# PAC55XX register map
Vendor: Active-Semi; Series: PAC55XX; File version: 1.0
CPU: CM4 r0p1, little endian, MPU, FPU, vendor SysTick, 3 interrupt priority bits
Registers are 32-bit, read-write, reset 0x0 unless marked. A register's access mark holds for its fields unless they carry their own. Offsets are from the block's base; [hi:lo] are bit positions; {n}, {i} and the like mark numbered series.

## TimerD
Base 0x40090000
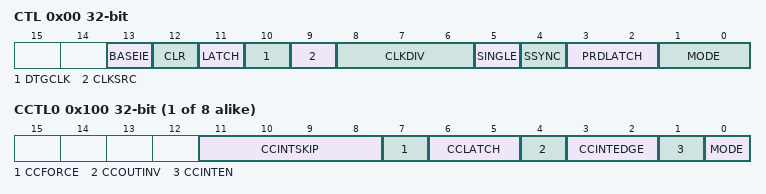
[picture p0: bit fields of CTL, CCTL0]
0x00 CTL — Timer D Control
  [13] BASEIE — Base timer interrupt enable
    0=Disabled (Base interrupt disabled); 1=Enabled (Base interrupt enabled)
  [12] CLR — Timer Clear
    0=Do not clear timer counter; 1=Clear timer counter
  [11] LATCH — Write 1 to Latch Period and all CCTRs
  [10] DTGCLK — Dead-Time Generator Clock Source
    0=Before Divider (Before input clock divider); 1=After Divider (After input clock divider)
  [9] CLKSRC — Timer Clock Source
    0=PCLK (PCLK selected as input to timer); 1=ACLK (ACLK selected as input to timer)
  [8:6] CLKDIV — Timer Input Clock Divider
    0=/1 (Timer input clock /1); 1=/2 (Timer input clock /2); 2=/4 (Timer input clock /4); 3=/8 (Timer input clock /8); 4=/16 (Timer input clock /16); 5=/32 (Timer input clock /32); 6=/64 (Timer input clock /64); 7=/128 (Timer input clock /128)
  [5] SINGLE — Single Shot Timer
    0=Disabled (Single Shot Disabled (auto-reload)); 1=Enabled (Single Shot Timer Enabled)
  [4] SSYNC — Timer Slave Synchronization
    0=Disabled (Slave Sync Disabled); 1=Enabled (Slave Sync Enabled)
  [3:2] PRDLATCH — Timer Period Latch Mode
    0=CTR=0 (Period is latched when CTR = 0); 1=CTR=Period (Period is latched when CTR = Period); 2=Immediate (Period is latched immediately upon register write)
  [1:0] MODE — Timer Mode
    0=Disabled Mode; 1=Up (Up Mode); 2=Up/Down Mode; 3=Asymmetric Mode
0x04 INT — Timer D Interrupt Control
0x08 PRD — Timer D Period
0x0C CTR — Timer D Counter
0x10 QEPCTL — Timer D QEP Control
{0x100+8i} CCTL{i} (i=0..7) — Timer D CC Control {i}
  [11:8] CCINTSKIP — CC Interrupt Skip Counter
    0=Don't skip CCR matches before interrupt; 1=Skip 1 CCR match before interrupt; {v}=Skip {v} CCR matches before interrupt (v=2..15)
  [7] CCFORCE — Write 1 to force compare event (self-clearing)
  [6:5] CCLATCH — CCR Register Latch Mode
    0=CTR=0/Rising (Compare(latch on CTR=0)/ Capture(latch on rising edge)); 1=CTR=Period/Falling (Compare(latch on CTR=Period)/ Capture(latch on falling edge)); 2=Immediate/Both (Compare(latch immediately)/ Capture(latch on both edges))
  [4] CCOUTINV — Invert CCR Output
    0=Not Inverted (Do not invert CCR output); 1=Inverted (Invert CCR output)
  [3:2] CCINTEDGE — Capture Mode Interrupt Edge Setting
    0=Rising Edge Interrupt; 1=Falling Edge Interrupt; 2=Both (Rising and Falling Edge Interrupt)
  [1] CCINTEN — CCR Interrupt Enable
    0=Disabled (CCR interrupt disabled); 1=Enabled (CCR interrupt enabled)
  [0] MODE — CCR Mode
    0=Compare Mode; 1=Capture Mode
{0x104+8i} CCTR{i} (i=0..7) — Timer D CC Counter {i}
{0x200+4i} DTGCTL{i} (i=0..3) — Timer D DTG Control {i}

## CAN — CAN Peripheral
Base 0x400A0000
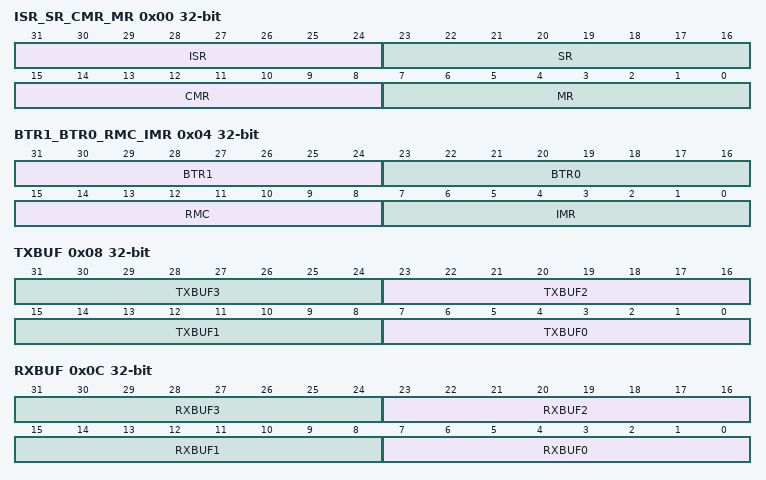
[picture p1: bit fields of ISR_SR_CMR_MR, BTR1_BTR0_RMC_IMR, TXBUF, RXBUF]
0x00 ISR_SR_CMR_MR — Combined CAN MR, CMR, SR, and ISR registers
  [31:24] ISR — CAN Interrupt Status/Acknowledge
  [23:16] SR — CAN Status
  [15:8] CMR — CAN Command
  [7:0] MR — CAN Mode
0x04 BTR1_BTR0_RMC_IMR — Combined CAN IMR, RMC, BTR0, and BTR1 registers
  [31:24] BTR1 — CAN Bus Timing Register 1
  [23:16] BTR0 — CAN Bus Timing Register 0
  [15:8] RMC — CAN Receive Message Counter
  [7:0] IMR — CAN Interrupt Mask
0x08 TXBUF — Combined CAN Transmit Buffer registers
  [8n+7:8n] TXBUF{n} (n=0..3) — CAN Transmit Buffer {n}
0x0C RXBUF — Combined CAN Receive Buffer registers
  [8n+7:8n] RXBUF{n} (n=0..3) — CAN Receive Buffer {n}
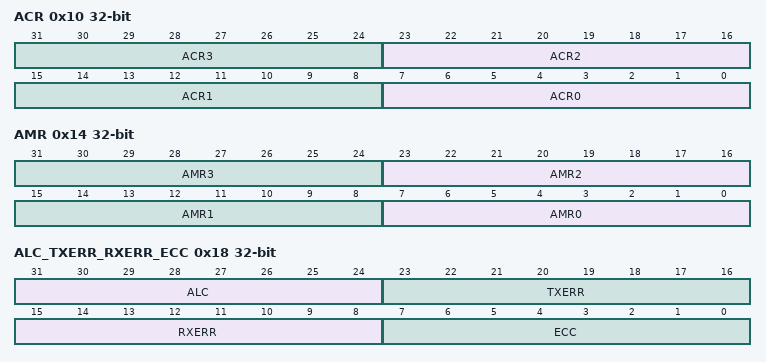
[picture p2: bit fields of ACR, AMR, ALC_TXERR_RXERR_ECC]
0x10 ACR — Combined CAN Acceptance Code registers
  [8n+7:8n] ACR{n} (n=0..3) — CAN Acceptance Code {n}
0x14 AMR — Combined CAN Acceptance Mask registers
  [8n+7:8n] AMR{n} (n=0..3) — CAN Acceptance Mask {n}
0x18 ALC_TXERR_RXERR_ECC — Combined CAN ECC, RXERR, TXERR, and ALC registers
  [31:24] ALC — CAN Arbitration Lost Code Capture
  [23:16] TXERR — CAN TX Error Counter
  [15:8] RXERR — CAN RX Error Counter
  [7:0] ECC — CAN Error Code Capture
